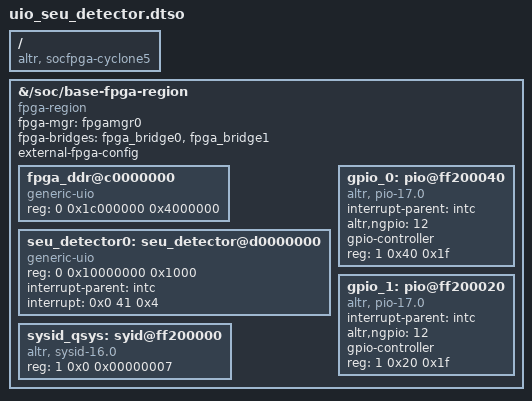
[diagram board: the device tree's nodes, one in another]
/dts-v1/; 
/plugin/;
/{
	compatible="altr, socfpga-cyclone5", "altr, socfpga";

	fragment@0{

		target-path = "/soc/base-fpga-region";

		#address-cells = <2>;
		#size-cells = <1>;
		
		__overlay__{
			compatible = "fpga-region";
			fpga-mgr = <&fpgamgr0>;
			fpga-bridges=<&fpga_bridge0>,<&fpga_bridge1>;

			#address-cells=<2>; 
			#size-cells=<1>;
			ranges = <0 0 0xc0000000 0x20000000>, 
				<1 0 0xff200000 0x00200000>;

			external-fpga-config;

			fpga_ddr@c0000000{
				compatible = "generic-uio"; 
				reg = <0 0x1c000000 0x4000000>;
			};
	
			seu_detector0: seu_detector@d0000000{
				compatible = "generic-uio";
				reg = <0 0x10000000 0x1000>;
				interrupt-parent = <&intc>;
				interrupt = <0x0 41 0x4>;
				interrupt-names = "bitflips";
			};


			sysid_qsys:syid@ff200000{
				compatible = "altr, sysid-16.0", "altr, sysid-1.0"; 
				reg = <1 0x0 0x00000007>;
			};

			gpio_0: pio@ff200040{
				compatible = "altr, pio-17.0", "altr, pio-1.0";
				interrupt-parent = <&intc>;		
				altr,ngpio = <12>;
				#gpio-cells = <2>;
				gpio-controller;

				reg=<1 0x40 0x1f>;
			};

			gpio_1:pio@ff200020{
				compatible = "altr, pio-17.0", "altr, pio-1.0";
				interrupt-parent = <&intc>;
				altr,ngpio = <12>;
				#gpio-cells = <2>;
				gpio-controller;

				reg=<1 0x20 0x1f>;
			};
		};
	};
};
